# ATSAMC21J18AU device description
Architecture: CORTEX-M0PLUS; Family: SAMC; Series: SAMC21
Registers are 32-bit, read-write, reset 0x0 unless marked. A register's access mark holds for its fields unless they carry their own. Offsets are from the block's base; [hi:lo] are bit positions; {n}, {i} and the like mark numbered series; 'fields as' and 'values as' point back to an identical list.

## AC — Analog Comparators
Instances: AC 0x42005000
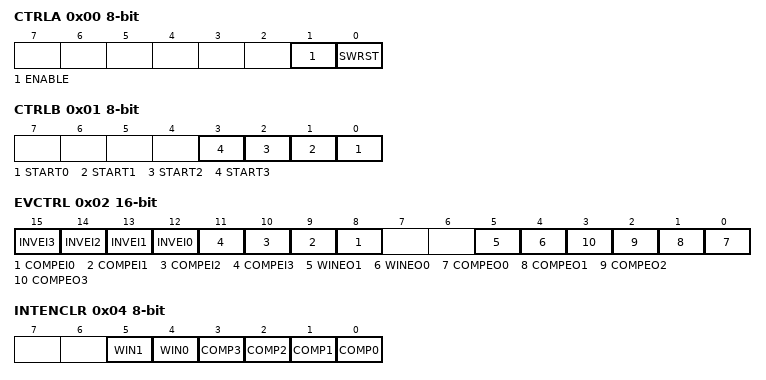
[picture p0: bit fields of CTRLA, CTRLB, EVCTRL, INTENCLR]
0x00 CTRLA 8-bit (WSYNC) — Control A
  [1] ENABLE
  [0] SWRST — Software Reset
0x01 CTRLB 8-bit wo — Control B
  [n] START{n} (n=0..3) — Comparator {n} Start Comparison
0x02 EVCTRL 16-bit — Event Control
  [n+12] INVEI{n} (n=0..3) — Comparator {n} Input Event Invert Enable
  [n+8] COMPEI{n} (n=0..3) — Comparator {n} Event Input Enable
  [5] WINEO1 — Window 1 Event Output Enable
  [4] WINEO0 — Window 0 Event Output Enable
  [n] COMPEO{n} (n=0..3) — Comparator {n} Event Output Enable
0x04 INTENCLR 8-bit (atomic clear) — Interrupt Enable Clear
  [5] WIN1 — Window 1 Interrupt Enable
  [4] WIN0 — Window 0 Interrupt Enable
  [n] COMP{n} (n=0..3) — Comparator {n} Interrupt Enable
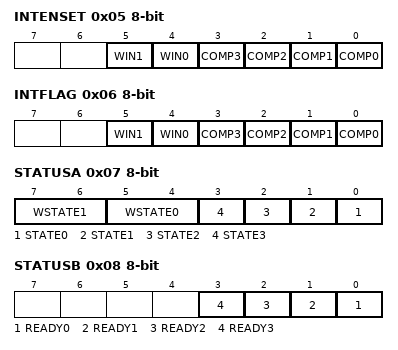
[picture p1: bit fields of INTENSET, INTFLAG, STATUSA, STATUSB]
0x05 INTENSET 8-bit (atomic set) — Interrupt Enable Set
  fields as INTENCLR
0x06 INTFLAG 8-bit (atomic clear) — Interrupt Flag Status and Clear
  [5] WIN1 — Window 1
  [4] WIN0 — Window 0
  [n] COMP{n} (n=0..3) — Comparator {n}
0x07 STATUSA 8-bit ro
  [7:6] WSTATE1 — Window 1 Current State
    0=ABOVE (Signal is above window); 1=INSIDE (Signal is inside window); 2=BELOW (Signal is below window)
  [5:4] WSTATE0 — Window 0 Current State
    values as WSTATE1
  [n] STATE{n} (n=0..3) — Comparator {n} Current State
0x08 STATUSB 8-bit ro
  [n] READY{n} (n=0..3) — Comparator {n} Ready
0x09 DBGCTRL 8-bit — Debug Control
  [0] DBGRUN — Debug Run
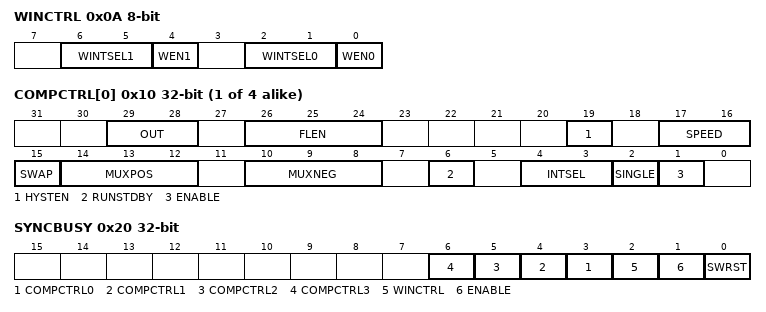
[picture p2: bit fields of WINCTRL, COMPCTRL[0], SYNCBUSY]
0x0A WINCTRL 8-bit (WSYNC) — Window Control
  [6:5] WINTSEL1 — Window 1 Interrupt Selection
    0=ABOVE (Interrupt on signal above window); 1=INSIDE (Interrupt on signal inside window); 2=BELOW (Interrupt on signal below window); 3=OUTSIDE (Interrupt on signal outside window)
  [4] WEN1 — Window 1 Mode Enable
  [2:1] WINTSEL0 — Window 0 Interrupt Selection
    values as WINTSEL1
  [0] WEN0 — Window 0 Mode Enable
{0xC+i} SCALER[{i}] (i=0..3) 8-bit — Scaler n
  [5:0] VALUE — Scaler Value
{0x10+4i} COMPCTRL[{i}] (i=0..3) — Comparator Control n
  [29:28] OUT — Output
    0=OFF (The output of COMPn is not routed to the COMPn I/O port); 1=ASYNC (The asynchronous output of COMPn is routed to the COMPn I/O port); 2=SYNC (The synchronous output (including filtering) of COMPn is routed to the COMPn I/O port)
  [26:24] FLEN — Filter Length
    0=OFF (No filtering); 1=MAJ3 (3-bit majority function (2 of 3)); 2=MAJ5 (5-bit majority function (3 of 5))
  [19] HYSTEN — Hysteresis Enable
  [17:16] SPEED — Speed Selection
    0=LOW (Low speed); 3=HIGH (High speed)
  [15] SWAP — Swap Inputs and Invert
  [14:12] MUXPOS — Positive Input Mux Selection
    {v}=PIN{v} (I/O pin {v}) (v=0..3); 4=VSCALE (VDD Scaler)
  [10:8] MUXNEG — Negative Input Mux Selection
    {v}=PIN{v} (I/O pin {v}) (v=0..3); 4=GND (Ground); 5=VSCALE (VDD scaler); 6=BANDGAP (Internal bandgap voltage); 7=DAC (DAC output)
  [6] RUNSTDBY — Run in Standby
  [4:3] INTSEL — Interrupt Selection
    0=TOGGLE (Interrupt on comparator output toggle); 1=RISING (Interrupt on comparator output rising); 2=FALLING (Interrupt on comparator output falling); 3=EOC (Interrupt on end of comparison (single-shot mode only))
  [2] SINGLE — Single-Shot Mode
  [1] ENABLE
0x20 SYNCBUSY ro — Synchronization Busy
  [n+3] COMPCTRL{n} (n=0..3) — COMPCTRL {n} Synchronization Busy
  [2] WINCTRL — WINCTRL Synchronization Busy
  [1] ENABLE — Enable Synchronization Busy
  [0] SWRST — Software Reset Synchronization Busy
Value list AC_COMPCTRL__HYST: 0=HYST50 (50mV); 1=HYST70 (70mV); 2=HYST90 (90mV); 3=HYST110 (110mV)

## CAN_RXBE — Rx Buffer Element
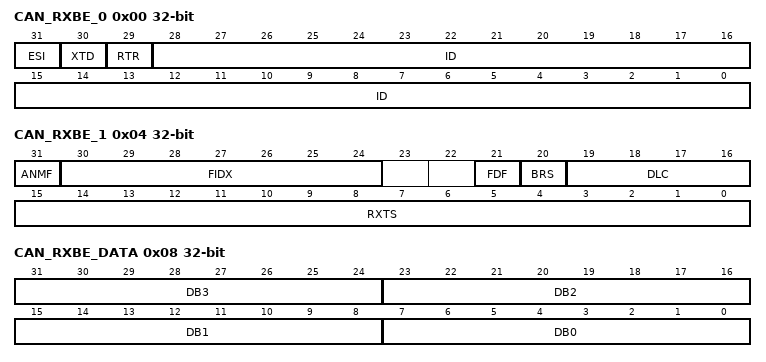
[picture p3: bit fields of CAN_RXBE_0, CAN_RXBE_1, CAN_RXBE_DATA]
0x00 CAN_RXBE_0 reset not defined — Rx Buffer Element 0
  [31] ESI — Error State Indicator
  [30] XTD — Extended Identifier
  [29] RTR — Remote Transmission Request
  [28:0] ID — Identifier
0x04 CAN_RXBE_1 reset not defined — Rx Buffer Element 1
  [31] ANMF — Accepted Non-matching Frame
  [30:24] FIDX — Filter Index
  [21] FDF — FD Format
  [20] BRS — Bit Rate Switch
  [19:16] DLC — Data Length Code
  [15:0] RXTS — Rx Timestamp
0x08 CAN_RXBE_DATA reset not defined — Rx Buffer Element Data
  [8n+7:8n] DB{n} (n=0..3) — Data Byte {n}

## Notices in the file
Copyright (c) 2018 Microchip Technology Inc.
SPDX-License-Identifier: Apache-2.0
Licensed under the Apache License, Version 2.0 (the "License");
you may not use this file except in compliance with the License.
You may obtain a copy of the License at
http://www.apache.org/licenses/LICENSE-2.0
Unless required by applicable law or agreed to in writing, software
distributed under the License is distributed on an "AS IS" BASIS,
WITHOUT WARRANTIES OR CONDITIONS OF ANY KIND, either express or implied.
See the License for the specific language governing permissions and
limitations under the License.
